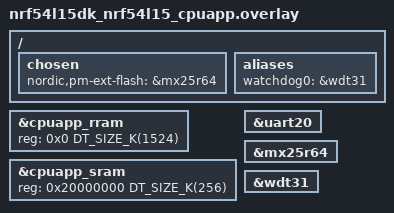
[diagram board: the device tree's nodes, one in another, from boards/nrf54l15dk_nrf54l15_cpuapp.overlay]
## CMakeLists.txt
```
#
# Copyright (c) 2025 Nordic Semiconductor ASA
#
# SPDX-License-Identifier: LicenseRef-Nordic-5-Clause
#

cmake_minimum_required(VERSION 3.20.0)

find_package(Zephyr HINTS $ENV{ZEPHYR_BASE})

project(matter-temperature-sensor)

# Enable GNU STD support.
include(${ZEPHYR_CONNECTEDHOMEIP_MODULE_DIR}/config/nrfconnect/app/enable-gnu-std.cmake)

# NORDIC SDK APP START

# Include all source files that are located in the Matter common directory.
include(${ZEPHYR_NRF_MODULE_DIR}/samples/matter/common/cmake/source_common.cmake)

# Include Data Model utils
include(${ZEPHYR_NRF_MODULE_DIR}/samples/matter/common/cmake/data_model.cmake)

include(${ZEPHYR_NRF_MODULE_DIR}/samples/matter/common/cmake/zap_helpers.cmake)
ncs_get_zap_parent_dir(ZAP_PARENT_DIR)

target_include_directories(app PRIVATE
  src
  ${ZAP_PARENT_DIR}
)

target_sources(app PRIVATE
  src/app_task.cpp
  src/main.cpp
)

ncs_configure_data_model()
# NORDIC SDK APP END
```

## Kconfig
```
#
# Copyright (c) 2025 Nordic Semiconductor
#
# SPDX-License-Identifier: LicenseRef-Nordic-5-Clause
#
mainmenu "Matter nRF Connect Temperature Sensor Example Application"

choice OPENTHREAD_NORDIC_LIBRARY_CONFIGURATION
	default OPENTHREAD_NORDIC_LIBRARY_MTD
endchoice

choice OPENTHREAD_DEVICE_TYPE
	default OPENTHREAD_MTD
endchoice

config CHIP_ENABLE_ICD_SUPPORT
	default y

config CHIP_ICD_LIT_SUPPORT
	default y

config CHIP_ICD_SIT_SLOW_POLL_LIMIT
	default 5000

config CHIP_ICD_REPORT_ON_ACTIVE_MODE
	default y

# Reduce Thread TX output power to 0 dBm for SED device
config OPENTHREAD_DEFAULT_TX_POWER
	default 0

source "$(ZEPHYR_CONNECTEDHOMEIP_MODULE_DIR)/config/nrfconnect/chip-module/Kconfig.features"
source "$(ZEPHYR_CONNECTEDHOMEIP_MODULE_DIR)/config/nrfconnect/chip-module/Kconfig.defaults"
source "$(ZEPHYR_NRF_MODULE_DIR)/samples/matter/common/src/Kconfig"
source "Kconfig.zephyr"
```

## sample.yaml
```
sample:
  description: Matter Temperature Sensor example
  name: Matter Temperature Sensor
common:
  tags:
    - sysbuild
    - ci_samples_matter
tests:
  sample.matter.temperature_sensor.debug:
    sysbuild: true
    build_only: true
    integration_platforms:
      - nrf52840dk/nrf52840
      - nrf5340dk/nrf5340/cpuapp
      - nrf54l15dk/nrf54l15/cpuapp
      - nrf54lm20dk/nrf54lm20a/cpuapp
    platform_allow:
      - nrf52840dk/nrf52840
      - nrf5340dk/nrf5340/cpuapp
      - nrf54l15dk/nrf54l15/cpuapp
      - nrf54lm20dk/nrf54lm20a/cpuapp
  sample.matter.temperature_sensor.release:
    sysbuild: true
    build_only: true
    extra_args:
      - FILE_SUFFIX=release
    integration_platforms:
      - nrf52840dk/nrf52840
      - nrf5340dk/nrf5340/cpuapp
      - nrf54l15dk/nrf54l15/cpuapp
      - nrf54lm20dk/nrf54lm20a/cpuapp
    platform_allow:
      - nrf52840dk/nrf52840
      - nrf5340dk/nrf5340/cpuapp
      - nrf54l15dk/nrf54l15/cpuapp
      - nrf54lm20dk/nrf54lm20a/cpuapp
```

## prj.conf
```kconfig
#
# Copyright (c) 2025 Nordic Semiconductor ASA
#
# SPDX-License-Identifier: LicenseRef-Nordic-5-Clause
#

# Enable CHIP
CONFIG_CHIP=y
CONFIG_CHIP_PROJECT_CONFIG="src/chip_project_config.h"
CONFIG_CHIP_DEVICE_PRODUCT_NAME="Matter Temperature Sensor"

# Configure ZAP file name
CONFIG_NCS_SAMPLE_MATTER_ZAP_FILE_PATH="${APPLICATION_CONFIG_DIR}/src/default_zap/temperature_sensor.zap"

# Based on https://github.com/project-chip/connectedhomeip/blob/482e6fd03196a6de45465a90003947ef4b86e0b1/docs/examples/discussion/PID_allocation_for_example_apps.md)
CONFIG_CHIP_DEVICE_PRODUCT_ID=32781
CONFIG_STD_CPP17=y

# Enable Matter pairing automatically on application start.
CONFIG_CHIP_ENABLE_PAIRING_AUTOSTART=y

# Enable Matter extended announcement and increase duration to 1 hour.
CONFIG_CHIP_BLE_EXT_ADVERTISING=y
CONFIG_CHIP_BLE_ADVERTISING_DURATION=60

# Add support for LEDs and buttons on Nordic development kits
CONFIG_DK_LIBRARY=y

# Bluetooth Low Energy configuration
CONFIG_BT_DEVICE_NAME="MatterTemperature"
CONFIG_BT_DEVICE_NAME_MAX=18

# Suspend devices when the CPU goes into sleep
CONFIG_PM_DEVICE=y

# Other settings
CONFIG_THREAD_NAME=y
CONFIG_MPU_STACK_GUARD=y
CONFIG_RESET_ON_FATAL_ERROR=n
CONFIG_CHIP_LIB_SHELL=y

# Reduce application size
CONFIG_USE_SEGGER_RTT=n

# Enable Factory Data feature
CONFIG_CHIP_FACTORY_DATA=y
CONFIG_CHIP_FACTORY_DATA_BUILD=y
```

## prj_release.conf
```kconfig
#
# Copyright (c) 2025 Nordic Semiconductor ASA
#
# SPDX-License-Identifier: LicenseRef-Nordic-5-Clause
#

# Enable CHIP
CONFIG_CHIP=y
CONFIG_CHIP_PROJECT_CONFIG="src/chip_project_config.h"
CONFIG_CHIP_DEVICE_PRODUCT_NAME="Matter Temperature Sensor"

# Configure ZAP file name
CONFIG_NCS_SAMPLE_MATTER_ZAP_FILE_PATH="${APPLICATION_CONFIG_DIR}/src/default_zap/temperature_sensor.zap"

# Based on https://github.com/project-chip/connectedhomeip/blob/482e6fd03196a6de45465a90003947ef4b86e0b1/docs/examples/discussion/PID_allocation_for_example_apps.md)
CONFIG_CHIP_DEVICE_PRODUCT_ID=32781
CONFIG_STD_CPP17=y

# Enable Matter pairing automatically on application start.
CONFIG_CHIP_ENABLE_PAIRING_AUTOSTART=y

# Enable Matter extended announcement and increase duration to 1 hour.
CONFIG_CHIP_BLE_EXT_ADVERTISING=y
CONFIG_CHIP_BLE_ADVERTISING_DURATION=60

# Add support for LEDs and buttons on Nordic development kits
CONFIG_DK_LIBRARY=y

# Try to disable unused RAM blocks to reduce power consumption
CONFIG_RAM_POWER_DOWN_LIBRARY=y

# Bluetooth Low Energy configuration
CONFIG_BT_DEVICE_NAME="MatterTemperature"
CONFIG_BT_DEVICE_NAME_MAX=18

# Suspend devices when the CPU goes into sleep
CONFIG_PM_DEVICE=y

# Enable system reset on fatal error
CONFIG_RESET_ON_FATAL_ERROR=y

# Disable all debug features
CONFIG_USE_SEGGER_RTT=n
CONFIG_SHELL=n
CONFIG_OPENTHREAD_SHELL=n
CONFIG_CONSOLE=n
CONFIG_UART_CONSOLE=n
CONFIG_SERIAL=n
CONFIG_LOG=n
CONFIG_LOG_MODE_MINIMAL=n
CONFIG_ASSERT_VERBOSE=n
CONFIG_ASSERT_NO_FILE_INFO=y
CONFIG_PRINTK=n
CONFIG_PRINTK_SYNC=n
CONFIG_THREAD_NAME=n
CONFIG_BOOT_BANNER=n

# Enable Factory Data feature
CONFIG_CHIP_FACTORY_DATA=y
CONFIG_CHIP_FACTORY_DATA_BUILD=y

# Enable Watchdog
CONFIG_NCS_SAMPLE_MATTER_WATCHDOG=y

# Enable LTO to decrease the flash usage.
CONFIG_LTO=y
CONFIG_ISR_TABLES_LOCAL_DECLARATION=y
```

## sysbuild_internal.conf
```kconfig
#
# Copyright (c) 2025 Nordic Semiconductor
#
# SPDX-License-Identifier: LicenseRef-Nordic-5-Clause
#

SB_CONFIG_MATTER=y
SB_CONFIG_PM_OVERRIDE_EXTERNAL_DRIVER_CHECK=n
SB_CONFIG_PM_EXTERNAL_FLASH_MCUBOOT_SECONDARY=n

# Enable the DFU image compression.
SB_CONFIG_MCUBOOT_MODE_OVERWRITE_ONLY=y
SB_CONFIG_MCUBOOT_COMPRESSED_IMAGE_SUPPORT=y
```

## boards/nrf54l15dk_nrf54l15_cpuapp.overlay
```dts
/*
 * Copyright (c) 2025 Nordic Semiconductor ASA
 *
 * SPDX-License-Identifier: LicenseRef-Nordic-5-Clause
 */


/ {
	chosen {
		nordic,pm-ext-flash = &mx25r64;
	};

	aliases {
		/* Use watchdog wdt31 as the application watchdog */
		watchdog0 = &wdt31;
	};
};

/* restore full RRAM and SRAM space - by default some parts are dedicated to FLRP */
&cpuapp_rram {
	reg = <0x0 DT_SIZE_K(1524)>;
};

&cpuapp_sram {
	reg = <0x20000000 DT_SIZE_K(256)>;
	ranges = <0x0 0x20000000  0x40000>;
};

/* TODO: re-enable HWFC once it's fixed */
&uart20 {
	/delete-property/ hw-flow-control;
};

&mx25r64 {
	status = "okay";
};

&wdt31 {
	status = "okay";
};
```

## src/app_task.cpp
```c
/*
 * Copyright (c) 2025 Nordic Semiconductor ASA
 *
 * SPDX-License-Identifier: LicenseRef-Nordic-5-Clause
 */

#include "app_task.h"

#include "app/matter_init.h"
#include "app/task_executor.h"
#include "board/board.h"
#include "clusters/identify.h"
#include "lib/core/CHIPError.h"

#include <app-common/zap-generated/attributes/Accessors.h>

#include <zephyr/logging/log.h>

LOG_MODULE_DECLARE(app, CONFIG_CHIP_APP_LOG_LEVEL);

using namespace ::chip;
using namespace ::chip::app;
using namespace ::chip::DeviceLayer;

namespace
{
constexpr chip::EndpointId kTemperatureSensorEndpointId = 1;

Nrf::Matter::IdentifyCluster sIdentifyCluster(kTemperatureSensorEndpointId);

#ifdef CONFIG_CHIP_ICD_UAT_SUPPORT
#define UAT_BUTTON_MASK DK_BTN3_MSK
#endif
} /* namespace */

void AppTask::ButtonEventHandler(Nrf::ButtonState state, Nrf::ButtonMask hasChanged)
{
#ifdef CONFIG_CHIP_ICD_UAT_SUPPORT
	if ((UAT_BUTTON_MASK & state & hasChanged)) {
		LOG_INF("ICD UserActiveMode has been triggered.");
		Server::GetInstance().GetICDManager().OnNetworkActivity();
	}
#endif
}

void AppTask::UpdateTemperatureTimeoutCallback(k_timer *timer)
{
	if (!timer || !timer->user_data) {
		return;
	}

	DeviceLayer::PlatformMgr().ScheduleWork(
		[](intptr_t p) {
			AppTask::Instance().UpdateTemperatureMeasurement();

			Protocols::InteractionModel::Status status =
				Clusters::TemperatureMeasurement::Attributes::MeasuredValue::Set(
					kTemperatureSensorEndpointId, AppTask::Instance().GetCurrentTemperature());

			if (status != Protocols::InteractionModel::Status::Success) {
				LOG_ERR("Updating temperature measurement failed %x", to_underlying(status));
			}
		},
		reinterpret_cast<intptr_t>(timer->user_data));
}

CHIP_ERROR AppTask::Init()
{
	/* Initialize Matter stack */
	ReturnErrorOnFailure(Nrf::Matter::PrepareServer());

	if (!Nrf::GetBoard().Init(ButtonEventHandler)) {
		LOG_ERR("User interface initialization failed.");
		return CHIP_ERROR_INCORRECT_STATE;
	}

	/* Register Matter event handler that controls the connectivity status LED based on the captured Matter network
	 * state. */
	ReturnErrorOnFailure(Nrf::Matter::RegisterEventHandler(Nrf::Board::DefaultMatterEventHandler, 0));

	ReturnErrorOnFailure(sIdentifyCluster.Init());

	return Nrf::Matter::StartServer();
}

CHIP_ERROR AppTask::StartApp()
{
	ReturnErrorOnFailure(Init());

	DataModel::Nullable<int16_t> val;
	Protocols::InteractionModel::Status status =
		Clusters::TemperatureMeasurement::Attributes::MinMeasuredValue::Get(kTemperatureSensorEndpointId, val);

	if (status != Protocols::InteractionModel::Status::Success || val.IsNull()) {
		LOG_ERR("Failed to get temperature measurement min value %x", to_underlying(status));
		return CHIP_ERROR_INCORRECT_STATE;
	}

	mTemperatureSensorMinValue = val.Value();

	status = Clusters::TemperatureMeasurement::Attributes::MaxMeasuredValue::Get(kTemperatureSensorEndpointId, val);

	if (status != Protocols::InteractionModel::Status::Success || val.IsNull()) {
		LOG_ERR("Failed to get temperature measurement max value %x", to_underlying(status));
		return CHIP_ERROR_INCORRECT_STATE;
	}

	mTemperatureSensorMaxValue = val.Value();

	k_timer_init(&mTimer, AppTask::UpdateTemperatureTimeoutCallback, nullptr);
	k_timer_user_data_set(&mTimer, this);
	k_timer_start(&mTimer, K_MSEC(kTemperatureMeasurementIntervalMs), K_MSEC(kTemperatureMeasurementIntervalMs));

	while (true) {
		Nrf::DispatchNextTask();
	}

	return CHIP_NO_ERROR;
}
```

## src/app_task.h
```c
/*
 * Copyright (c) 2025 Nordic Semiconductor ASA
 *
 * SPDX-License-Identifier: LicenseRef-Nordic-5-Clause
 */

#pragma once

#include "board/board.h"

#include <platform/CHIPDeviceLayer.h>

struct Identify;

class AppTask {
public:
	static AppTask &Instance()
	{
		static AppTask sAppTask;
		return sAppTask;
	};

	CHIP_ERROR StartApp();

	/* Defined by cluster temperature measured value = 100 x temperature in degC with resolution of
	 * 0.01 degC. */
	void UpdateTemperatureMeasurement()
	{
		/* Linear temperature increase that is wrapped around to min value after reaching the max value. */
		if (mCurrentTemperature < mTemperatureSensorMaxValue) {
			mCurrentTemperature += kTemperatureMeasurementStep;
		} else {
			mCurrentTemperature = mTemperatureSensorMinValue;
		}
	}

	int16_t GetCurrentTemperature() const { return mCurrentTemperature; }

private:
	CHIP_ERROR Init();
	k_timer mTimer;

	static constexpr uint16_t kTemperatureMeasurementIntervalMs = 10000; /* 10 seconds */
	static constexpr uint16_t kTemperatureMeasurementStep = 100; /* 1 degree Celsius */

	static void UpdateTemperatureTimeoutCallback(k_timer *timer);

	static void ButtonEventHandler(Nrf::ButtonState state, Nrf::ButtonMask hasChanged);

	int16_t mTemperatureSensorMaxValue = 0;
	int16_t mTemperatureSensorMinValue = 0;
	int16_t mCurrentTemperature = 0;
};
```
